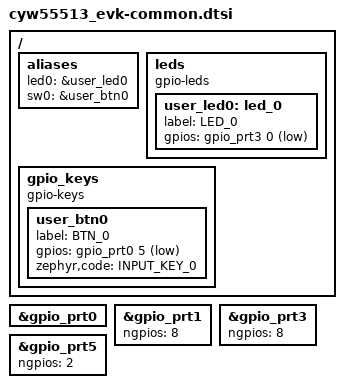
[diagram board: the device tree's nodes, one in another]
/*
 * Copyright (c) 2026 Infineon Technologies AG.
 * SPDX-License-Identifier: Apache-2.0
 */

#include <zephyr/dt-bindings/input/input-event-codes.h>

/ {
	aliases {
		led0 = &user_led0;
		sw0 = &user_btn0;
	};

	leds {
		compatible = "gpio-leds";

		user_led0: led_0 {
			label = "LED_0";
			gpios = <&gpio_prt3 0 GPIO_ACTIVE_LOW>;
		};
	};

	gpio_keys {
		compatible = "gpio-keys";

		user_btn0: user_btn0 {
			label = "BTN_0";
			gpios = <&gpio_prt0 5 (GPIO_PULL_UP | GPIO_ACTIVE_LOW)>;
			zephyr,code = <INPUT_KEY_0>;
		};
	};
};

/* GPIO Port configuration for CYW20829B0LKML variant */
&gpio_prt0 {
	status = "okay";
};

&gpio_prt1 {
	ngpios = <8>;
	status = "okay";
};

&gpio_prt3 {
	ngpios = <8>;
	status = "okay";
};

&gpio_prt5 {
	ngpios = <2>;
	status = "okay";
};
